# TC37XPD register map
Vendor: Infineon; Series: ATVMC; File version: 100
CPU: other r0p0, little endian, MPU, FPU, vendor SysTick, 4 interrupt priority bits
Registers are 32-bit, read-write, reset 0x0 unless marked. A register's access mark holds for its fields unless they carry their own. Offsets are from the block's base; [hi:lo] are bit positions; lines under a group give offsets from that group; {n}, {i} and the like mark numbered series.

## GTM (part 9 of 13)
Base 0xF0100000
{0xE4000+0x400*i} CDTM[{i}] (i=0..4) group
  {0x0+0x40*j} DTM[{j}] (j=0..5) group
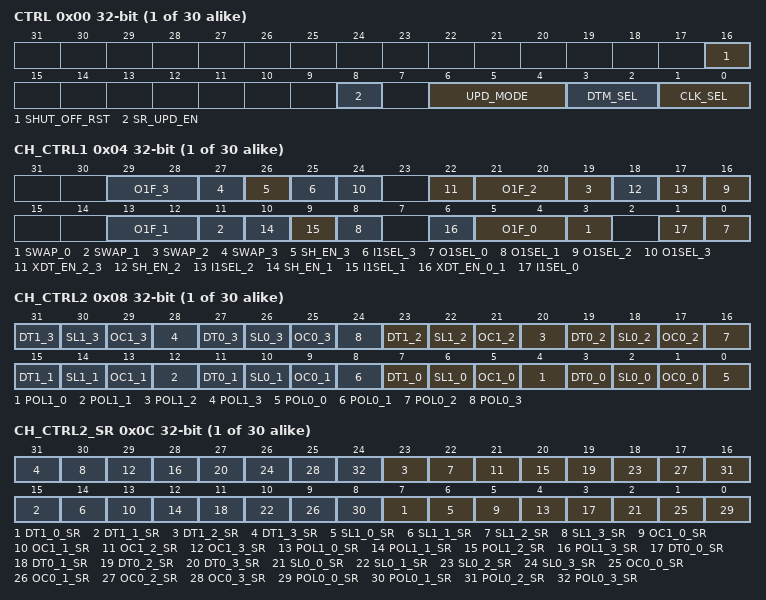
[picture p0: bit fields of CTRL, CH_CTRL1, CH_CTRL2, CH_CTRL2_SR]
    0x00 CTRL — CDTM0 DTM0 Global Configuration and Control Register resetvalue={Application Reset:0x0}
      [16] SHUT_OFF_RST — Shut off reset. Writing a 1 releases shut off resets signal SHUT OFF SYNC if selected by UPD MODE 2 0 0b001
      [8] SR_UPD_EN — Shadow register update enable
      [6:4] UPD_MODE — Update mode. Note If an INx edge is not implemented the value is unused. A write with this unused value returns 0b10 on status.
      [3:2] DTM_SEL — Select DTM update and SHUT OFF reset signal. 0X B 160 160 160 Shut off by signal TIM CH IN0 TIM CH IN1 or DTM AUX IN 1X B 160 160 160 Shut off by signal DTM i 1 PSU IN
      [1:0] CLK_SEL — Clock source select
    0x04 CH_CTRL1 — CDTM0 DTM0 Channel Control Register 1 resetvalue={Application Reset:0x0}
      [8n+5:8n+4] O1F_{n} (n=0..3) — Output 1 function channel {n}
      [8n+3] SWAP_{n} (n=0..3) — Swap outputs DTM i CH {n} OUT0 and DTM i CH {n} OUT1 before final output register
      [26] SH_EN_3 — Shift enable channel 3
      [25] I1SEL_3 — Input 1 select channel 3
      [8n] O1SEL_{n} (n=0..3) — Output 1 select channel {n}
      [22] XDT_EN_2_3 — Cross dead time enable on channels 0 and 1. Note TSEL0 x and SH EN x must be 0 for using cross dead time to avoid wrong input signals. x 2 3
      [18] SH_EN_2 — Shift enable channel 2
      [17] I1SEL_2 — Input 1 select channel 2
      [10] SH_EN_1 — Shift enable channel 1
      [9] I1SEL_1 — Input 1 select channel 1
      [6] XDT_EN_0_1 — Cross dead time enable on channels 0 and 1. Note TSEL0 x and SH EN 1 must be 0 for using cross dead time to avoid wrong input signals. x 0 1
      [1] I1SEL_0 — Input 1 select channel 0. Note If i is even I1SEL 0 is not implemented. Then the bit is read as zero and shall be written as zero.
    0x08 CH_CTRL2 — CDTM0 DTM0 Channel Control Register 2 resetvalue={Application Reset:0x0}
      [8n+7] DT1_{n} (n=0..3) — Dead time path enable on output 1 channel {n}
      [8n+6] SL1_{n} (n=0..3) — Signal level on output 1 channel {n}
      [8n+5] OC1_{n} (n=0..3) — Output 1 control channel {n}
      [8n+4] POL1_{n} (n=0..3) — Polarity on output 1 channel {n}
      [8n+3] DT0_{n} (n=0..3) — Dead time path enable on output 0 channel {n}
      [8n+2] SL0_{n} (n=0..3) — Signal level on output 0 channel {n}
      [8n+1] OC0_{n} (n=0..3) — Output 0 control channel {n}
      [8n] POL0_{n} (n=0..3) — Polarity on output 0 channel {n}
    0x0C CH_CTRL2_SR — CDTM0 DTM0 Channel Control Register 2 Shadow resetvalue={Application Reset:0x0}
      [8n+7] DT1_{n}_SR (n=0..3) — Dead time path enable on output 1 channel {n} shadow register
      [8n+6] SL1_{n}_SR (n=0..3) — Signal level on output 1 channel {n} shadow register
      [8n+5] OC1_{n}_SR (n=0..3) — Output 1 control channel {n} shadow register
      [8n+4] POL1_{n}_SR (n=0..3) — Polarity on output 1 channel {n} shadow register
      [8n+3] DT0_{n}_SR (n=0..3) — Dead time path enable on output 0 channel {n} shadow register
      [8n+2] SL0_{n}_SR (n=0..3) — Signal level on output 0 channel {n} shadow register
      [8n+1] OC0_{n}_SR (n=0..3) — Output 0 control channel {n} shadow register
      [8n] POL0_{n}_SR (n=0..3) — Polarity on output 0 channel {n} shadow register
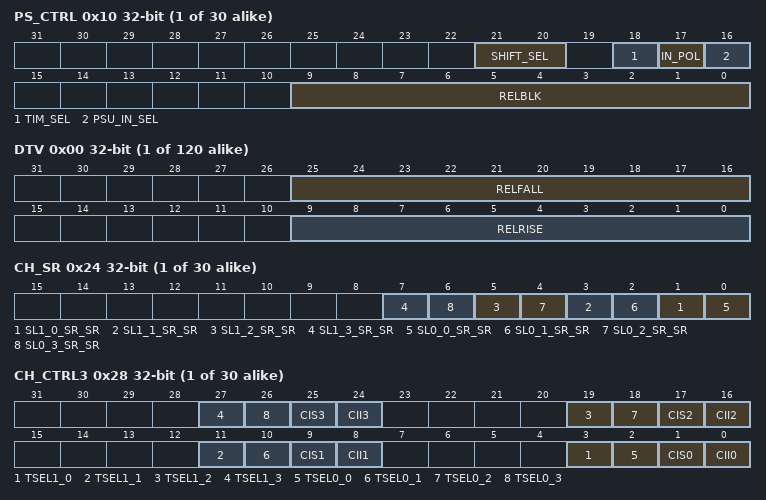
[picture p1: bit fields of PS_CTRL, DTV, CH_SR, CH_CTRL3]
    0x10 PS_CTRL — CDTM0 DTM0 Phase Shift Unit Configuration and Control Register resetvalue={Application Reset:0x0}
      [21:20] SHIFT_SEL — Shift select. Note If a channel is not implemented the value is unused. A write with this unused value returns 0b10 on status.
      [18] TIM_SEL — TIM input selection
      [17] IN_POL — Input polarity
      [16] PSU_IN_SEL — PSU input selection
      [9:0] RELBLK — Reload value blanking window. A value of 0x000 resets counter BLK DOWN CNT.
    {0x14+4k} CH[{k}] (k=0..3) group
      0x00 DTV — CDTM0 DTM0 Channel 0 Dead Time Reload Values resetvalue={Application Reset:0x0}
        [25:16] RELFALL — Reload value for falling edge dead time
        [9:0] RELRISE — Reload value for rising edge dead time
    0x24 CH_SR — CDTM0 DTM0 Channel Shadow Register resetvalue={Application Reset:0x0}
      [2n+1] SL1_{n}_SR_SR (n=0..3) — Shadow register for bit SL1 {n} SR of register DTM i CH CTRL2 SR
      [2n] SL0_{n}_SR_SR (n=0..3) — Shadow register for bit SL0 {n} SR of register DTM i CH CTRL2 SR
    0x28 CH_CTRL3 — CDTM0 DTM0 Channel Control Register 3 resetvalue={Application Reset:0x0}
      [8n+3] TSEL1_{n} (n=0..3) — Input selection combinational logic path
      [8n+2] TSEL0_{n} (n=0..3) — Input selection for dead time edge trigger generation
      [8n+1] CIS{n} (n=0..3) — Combinational input select channel {n}
      [8n] CII{n} (n=0..3) — Combinational input invert channel {n}
